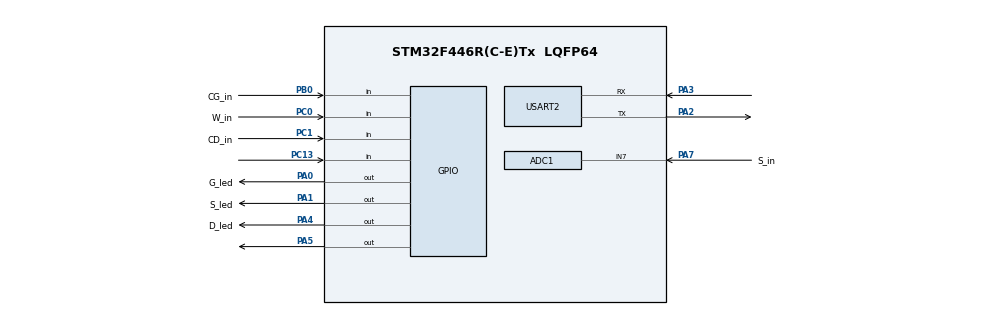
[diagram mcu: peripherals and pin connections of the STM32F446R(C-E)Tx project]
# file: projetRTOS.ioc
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ADC1.Channel-1\#ChannelRegularConversion=ADC_CHANNEL_7
ADC1.NbrOfConversionFlag=1
ADC1.Rank-1\#ChannelRegularConversion=1
ADC1.SamplingTime-1\#ChannelRegularConversion=ADC_SAMPLETIME_3CYCLES
ADC1.master=1
FREERTOS.Tasks01=task_1,24,128,StartDefaultTask,Default,NULL,Dynamic,NULL,NULL;task_2,16,128,StartTask02,Default,NULL,Dynamic,NULL,NULL
FREERTOS.configUSE_NEWLIB_REENTRANT=1
Mcu.Family=STM32F4
Mcu.Name=STM32F446R(C-E)Tx
Mcu.Package=LQFP64
NVIC.PriorityGroup=NVIC_PRIORITYGROUP_4
NVIC.TIM6_DAC_IRQn=true\:15\:0\:false\:false\:true\:false\:false\:true\:true
NVIC.TimeBase=TIM6_DAC_IRQn
NVIC.TimeBaseIP=TIM6
PA0-WKUP.GPIO_Label=G_led
PA0-WKUP.Signal=GPIO_Output
PA1.GPIO_Label=S_led
PA1.Signal=GPIO_Output
PA13.Mode=Serial_Wire
PA13.Signal=SYS_JTMS-SWDIO
PA14.Mode=Serial_Wire
PA14.Signal=SYS_JTCK-SWCLK
PA2.Mode=Asynchronous
PA2.Signal=USART2_TX
PA3.Mode=Asynchronous
PA3.Signal=USART2_RX
PA4.GPIO_Label=D_led
PA4.Signal=GPIO_Output
PA5.Signal=GPIO_Output
PA7.GPIO_Label=S_in
PA7.Signal=ADCx_IN7
PB0.GPIO_Label=CG_in
PB0.Signal=GPIO_Input
PC0.GPIO_Label=W_in
PC0.Signal=GPIO_Input
PC1.GPIO_Label=CD_in
PC1.Signal=GPIO_Input
PC13.GPIO_PuPd=GPIO_PULLUP
PC13.Signal=GPIO_Input
ProjectManager.HeapSize=0x200
ProjectManager.StackSize=0x400
ProjectManager.TargetToolchain=STM32CubeIDE
RCC.CortexFreq_Value=16000000
RCC.USBFreq_Value=96000000
RCC.VCOOutputFreq_Value=192000000
SH.ADCx_IN7.0=ADC1_IN7,IN7
USART2.VirtualMode=VM_ASYNC
VP_FREERTOS_VS_CMSIS_V2.Mode=CMSIS_V2
VP_SYS_VS_tim6.Mode=TIM6
board=custom

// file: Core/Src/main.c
/* USER CODE BEGIN Header */
/**
  ******************************************************************************
  * @file           : main.c
  * @brief          : Main program body
  ******************************************************************************
  * @attention
  *
  * Copyright (c) 2023 STMicroelectronics.
  * All rights reserved.
  *
  * This software is licensed under terms that can be found in the LICENSE file
  * in the root directory of this software component.
  * If no LICENSE file comes with this software, it is provided AS-IS.
  *
  ******************************************************************************
  */
/* USER CODE END Header */
#include "main.h"
#include "cmsis_os.h"

/* USER CODE BEGIN Includes */
#include <string.h>

/* USER CODE END Includes */

ADC_HandleTypeDef hadc1;

UART_HandleTypeDef huart2;

/* Definitions for task_1 */
osThreadId_t task_1Handle;
const osThreadAttr_t task_1_attributes = {
  .name = "task_1",
  .stack_size = 128 * 4,
  .priority = (osPriority_t) osPriorityNormal,
};
/* Definitions for task_2 */
osThreadId_t task_2Handle;
const osThreadAttr_t task_2_attributes = {
  .name = "task_2",
  .stack_size = 128 * 4,
  .priority = (osPriority_t) osPriorityBelowNormal,
};

void SystemClock_Config(void);
static void MX_GPIO_Init(void);
static void MX_USART2_UART_Init(void);
static void MX_ADC1_Init(void);
void StartDefaultTask(void *argument);
void StartTask02(void *argument);

/* USER CODE BEGIN PFP */
void printUART(uint8_t *data);
/* USER CODE END PFP */

int main(void)
{

  /* MCU Configuration--------------------------------------------------------*/

  /* Reset of all peripherals, Initializes the Flash interface and the Systick. */
  HAL_Init();

  /* Configure the system clock */
  SystemClock_Config();

  /* Initialize all configured peripherals */
  MX_GPIO_Init();
  MX_USART2_UART_Init();
  MX_ADC1_Init();

  /* Init scheduler */
  osKernelInitialize();

  /* Create the thread(s) */
  /* creation of task_1 */
  task_1Handle = osThreadNew(StartDefaultTask, NULL, &task_1_attributes);

  /* creation of task_2 */
  task_2Handle = osThreadNew(StartTask02, NULL, &task_2_attributes);

  /* Start scheduler */
  osKernelStart();

  /* We should never get here as control is now taken by the scheduler */
  /* Infinite loop */
  while (1)
  {

  }
}

void SystemClock_Config(void)
{
  RCC_OscInitTypeDef RCC_OscInitStruct = {0};
  RCC_ClkInitTypeDef RCC_ClkInitStruct = {0};

  /** Configure the main internal regulator output voltage
  */
  __HAL_RCC_PWR_CLK_ENABLE();
  __HAL_PWR_VOLTAGESCALING_CONFIG(PWR_REGULATOR_VOLTAGE_SCALE3);

  /** Initializes the RCC Oscillators according to the specified parameters
  * in the RCC_OscInitTypeDef structure.
  */
  RCC_OscInitStruct.OscillatorType = RCC_OSCILLATORTYPE_HSI;
  RCC_OscInitStruct.HSIState = RCC_HSI_ON;
  RCC_OscInitStruct.HSICalibrationValue = RCC_HSICALIBRATION_DEFAULT;
  RCC_OscInitStruct.PLL.PLLState = RCC_PLL_NONE;
  if (HAL_RCC_OscConfig(&RCC_OscInitStruct) != HAL_OK)
  {
    Error_Handler();
  }

  /** Initializes the CPU, AHB and APB buses clocks
  */
  RCC_ClkInitStruct.ClockType = RCC_CLOCKTYPE_HCLK|RCC_CLOCKTYPE_SYSCLK
                              |RCC_CLOCKTYPE_PCLK1|RCC_CLOCKTYPE_PCLK2;
  RCC_ClkInitStruct.SYSCLKSource = RCC_SYSCLKSOURCE_HSI;
  RCC_ClkInitStruct.AHBCLKDivider = RCC_SYSCLK_DIV1;
  RCC_ClkInitStruct.APB1CLKDivider = RCC_HCLK_DIV1;
  RCC_ClkInitStruct.APB2CLKDivider = RCC_HCLK_DIV1;

  if (HAL_RCC_ClockConfig(&RCC_ClkInitStruct, FLASH_LATENCY_0) != HAL_OK)
  {
    Error_Handler();
  }
}

static void MX_ADC1_Init(void)
{

  ADC_ChannelConfTypeDef sConfig = {0};

  /** Configure the global features of the ADC (Clock, Resolution, Data Alignment and number of conversion)
  */
  hadc1.Instance = ADC1;
  hadc1.Init.ClockPrescaler = ADC_CLOCK_SYNC_PCLK_DIV2;
  hadc1.Init.Resolution = ADC_RESOLUTION_12B;
  hadc1.Init.ScanConvMode = DISABLE;
  hadc1.Init.ContinuousConvMode = DISABLE;
  hadc1.Init.DiscontinuousConvMode = DISABLE;
  hadc1.Init.ExternalTrigConvEdge = ADC_EXTERNALTRIGCONVEDGE_NONE;
  hadc1.Init.ExternalTrigConv = ADC_SOFTWARE_START;
  hadc1.Init.DataAlign = ADC_DATAALIGN_RIGHT;
  hadc1.Init.NbrOfConversion = 1;
  hadc1.Init.DMAContinuousRequests = DISABLE;
  hadc1.Init.EOCSelection = ADC_EOC_SINGLE_CONV;
  if (HAL_ADC_Init(&hadc1) != HAL_OK)
  {
    Error_Handler();
  }

  /** Configure for the selected ADC regular channel its corresponding rank in the sequencer and its sample time.
  */
  sConfig.Channel = ADC_CHANNEL_7;
  sConfig.Rank = 1;
  sConfig.SamplingTime = ADC_SAMPLETIME_3CYCLES;
  if (HAL_ADC_ConfigChannel(&hadc1, &sConfig) != HAL_OK)
  {
    Error_Handler();
  }

}

static void MX_USART2_UART_Init(void)
{

  huart2.Instance = USART2;
  huart2.Init.BaudRate = 115200;
  huart2.Init.WordLength = UART_WORDLENGTH_8B;
  huart2.Init.StopBits = UART_STOPBITS_1;
  huart2.Init.Parity = UART_PARITY_NONE;
  huart2.Init.Mode = UART_MODE_TX_RX;
  huart2.Init.HwFlowCtl = UART_HWCONTROL_NONE;
  huart2.Init.OverSampling = UART_OVERSAMPLING_16;
  if (HAL_UART_Init(&huart2) != HAL_OK)
  {
    Error_Handler();
  }

}

static void MX_GPIO_Init(void)
{
  GPIO_InitTypeDef GPIO_InitStruct = {0};

  /* GPIO Ports Clock Enable */
  __HAL_RCC_GPIOC_CLK_ENABLE();
  __HAL_RCC_GPIOA_CLK_ENABLE();
  __HAL_RCC_GPIOB_CLK_ENABLE();

  /*Configure GPIO pin Output Level */
  HAL_GPIO_WritePin(GPIOA, G_led_Pin|S_led_Pin|D_led_Pin|GPIO_PIN_5, GPIO_PIN_RESET);

  /*Configure GPIO pin : PC13 */
  GPIO_InitStruct.Pin = GPIO_PIN_13;
  GPIO_InitStruct.Mode = GPIO_MODE_INPUT;
  GPIO_InitStruct.Pull = GPIO_PULLUP;
  HAL_GPIO_Init(GPIOC, &GPIO_InitStruct);

  /*Configure GPIO pins : W_in_Pin CD_in_Pin */
  GPIO_InitStruct.Pin = W_in_Pin|CD_in_Pin;
  GPIO_InitStruct.Mode = GPIO_MODE_INPUT;
  GPIO_InitStruct.Pull = GPIO_NOPULL;
  HAL_GPIO_Init(GPIOC, &GPIO_InitStruct);

  /*Configure GPIO pins : G_led_Pin S_led_Pin D_led_Pin PA5 */
  GPIO_InitStruct.Pin = G_led_Pin|S_led_Pin|D_led_Pin|GPIO_PIN_5;
  GPIO_InitStruct.Mode = GPIO_MODE_OUTPUT_PP;
  GPIO_InitStruct.Pull = GPIO_NOPULL;
  GPIO_InitStruct.Speed = GPIO_SPEED_FREQ_LOW;
  HAL_GPIO_Init(GPIOA, &GPIO_InitStruct);

  /*Configure GPIO pin : CG_in_Pin */
  GPIO_InitStruct.Pin = CG_in_Pin;
  GPIO_InitStruct.Mode = GPIO_MODE_INPUT;
  GPIO_InitStruct.Pull = GPIO_NOPULL;
  HAL_GPIO_Init(CG_in_GPIO_Port, &GPIO_InitStruct);

}

/* USER CODE BEGIN 4 */
void printUART(uint8_t *data)
{
	HAL_UART_Transmit(&huart2 , data, strlen((char*)data) , 500);

}

/* USER CODE END 4 */

void StartDefaultTask(void *argument)
{
  /* USER CODE BEGIN 5 */
  /* Infinite loop */
  for(;;)
  {
	HAL_GPIO_TogglePin(GPIOA, GPIO_PIN_5);
    osDelay(500);
    printUART((uint8_t*)"task1");
  }
  /* USER CODE END 5 */
}

void StartTask02(void *argument)
{
  /* USER CODE BEGIN StartTask02 */
  /* Infinite loop */
  for(;;)
  {
	  HAL_GPIO_TogglePin(GPIOA, GPIO_PIN_5);
	  osDelay(5);
	  HAL_GPIO_TogglePin(GPIOA, GPIO_PIN_5);
	  printUART((uint8_t*)"tark2");
	  osDelay(239);
  }
  /* USER CODE END StartTask02 */
}

void HAL_TIM_PeriodElapsedCallback(TIM_HandleTypeDef *htim)
{
  if (htim->Instance == TIM6) {
    HAL_IncTick();
  }
}

void Error_Handler(void)
{
  __disable_irq();
  while (1)
  {
  }
}
